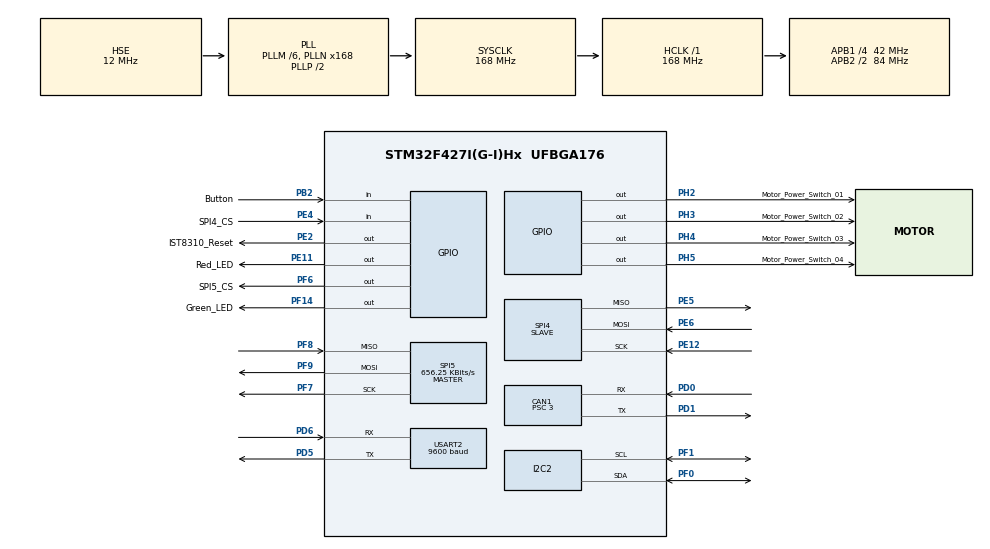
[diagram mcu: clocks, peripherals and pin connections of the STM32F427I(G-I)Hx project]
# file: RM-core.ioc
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CAN1.ABOM=ENABLE
CAN1.BS1=CAN_BS1_9TQ
CAN1.BS2=CAN_BS2_4TQ
CAN1.CalculateTimeQuantum=71.42857142857143
CAN1.Prescaler=3
FREERTOS.Tasks01=defaultTask,24,3000,StartDefaultTask,Default,NULL,Dynamic,NULL,NULL;myTask02,24,1024,StartTask02,Default,NULL,Static,myTask02Buffer,myTask02ControlBlock
FREERTOS.configTOTAL_HEAP_SIZE=15360
Mcu.Family=STM32F4
Mcu.Name=STM32F427I(G-I)Hx
Mcu.Package=UFBGA176
NVIC.CAN1_RX0_IRQn=true\:5\:0\:false\:false\:true\:true\:true\:true
NVIC.CAN1_TX_IRQn=true\:5\:0\:false\:false\:true\:true\:true\:true
NVIC.PriorityGroup=NVIC_PRIORITYGROUP_4
NVIC.TIM8_BRK_TIM12_IRQn=true\:0\:0\:false\:false\:true\:false\:false\:true
NVIC.TimeBase=TIM8_BRK_TIM12_IRQn
NVIC.TimeBaseIP=TIM12
NVIC.USART2_IRQn=true\:5\:0\:false\:false\:true\:true\:true\:true
PB2/BOOT1.GPIO_Label=Button
PB2/BOOT1.Signal=GPIO_Input
PD0.Mode=Master
PD0.Signal=CAN1_RX
PD1.Mode=Master
PD1.Signal=CAN1_TX
PD5.Mode=Asynchronous
PD5.Signal=USART2_TX
PD6.Mode=Asynchronous
PD6.Signal=USART2_RX
PE11.GPIO_Label=Red_LED
PE11.Signal=GPIO_Output
PE12.Mode=Full_Duplex_Slave
PE12.Signal=SPI4_SCK
PE2.GPIO_Label=IST8310_Reset
PE2.GPIO_Speed=GPIO_SPEED_FREQ_LOW
PE2.PinState=GPIO_PIN_SET
PE2.Signal=GPIO_Output
PE4.GPIO_Label=SPI4_CS
PE4.Signal=GPIO_Input
PE5.Mode=Full_Duplex_Slave
PE5.Signal=SPI4_MISO
PE6.Mode=Full_Duplex_Slave
PE6.Signal=SPI4_MOSI
PF0.Mode=I2C
PF0.Signal=I2C2_SDA
PF1.Mode=I2C
PF1.Signal=I2C2_SCL
PF14.GPIO_Label=Green_LED
PF14.Signal=GPIO_Output
PF6.GPIO_Label=SPI5_CS
PF6.GPIO_Speed=GPIO_SPEED_FREQ_VERY_HIGH
PF6.PinState=GPIO_PIN_SET
PF6.Signal=GPIO_Output
PF7.Mode=Full_Duplex_Master
PF7.Signal=SPI5_SCK
PF8.Mode=Full_Duplex_Master
PF8.Signal=SPI5_MISO
PF9.Mode=Full_Duplex_Master
PF9.Signal=SPI5_MOSI
PH0/OSC_IN.Mode=HSE-External-Oscillator
PH0/OSC_IN.Signal=RCC_OSC_IN
PH1/OSC_OUT.Mode=HSE-External-Oscillator
PH1/OSC_OUT.Signal=RCC_OSC_OUT
PH2.GPIO_Label=Motor_Power_Switch_01
PH2.Signal=GPIO_Output
PH3.GPIO_Label=Motor_Power_Switch_02
PH3.Signal=GPIO_Output
PH4.GPIO_Label=Motor_Power_Switch_03
PH4.Signal=GPIO_Output
PH5.GPIO_Label=Motor_Power_Switch_04
PH5.Signal=GPIO_Output
ProjectManager.HeapSize=0x200
ProjectManager.StackSize=0x400
ProjectManager.TargetToolchain=Makefile
RCC.48MHZClocksFreq_Value=84000000
RCC.AHBFreq_Value=168000000
RCC.APB1CLKDivider=RCC_HCLK_DIV4
RCC.APB1Freq_Value=42000000
RCC.APB1TimFreq_Value=84000000
RCC.APB2CLKDivider=RCC_HCLK_DIV2
RCC.APB2Freq_Value=84000000
RCC.APB2TimFreq_Value=168000000
RCC.CortexFreq_Value=168000000
RCC.HCLKFreq_Value=168000000
RCC.HSE_VALUE=12000000
RCC.HSI_VALUE=16000000
RCC.LSE_VALUE=32768
RCC.PLLM=6
RCC.PLLN=168
RCC.PLLSourceVirtual=RCC_PLLSOURCE_HSE
RCC.SYSCLKFreq_VALUE=168000000
RCC.SYSCLKSource=RCC_SYSCLKSOURCE_PLLCLK
RCC.VCOOutputFreq_Value=336000000
SPI4.CLKPhase=SPI_PHASE_1EDGE
SPI4.CRCCalculation=SPI_CRCCALCULATION_DISABLE
SPI4.Direction=SPI_DIRECTION_2LINES
SPI4.Mode=SPI_MODE_SLAVE
SPI4.TIMode=SPI_TIMODE_DISABLE
SPI4.VirtualType=VM_SLAVE
SPI5.BaudRatePrescaler=SPI_BAUDRATEPRESCALER_128
SPI5.CalculateBaudRate=656.25 KBits/s
SPI5.Direction=SPI_DIRECTION_2LINES
SPI5.Mode=SPI_MODE_MASTER
SPI5.VirtualType=VM_MASTER
USART2.BaudRate=9600
USART2.VirtualMode=VM_ASYNC
VP_FREERTOS_VS_CMSIS_V2.Mode=CMSIS_V2
VP_SYS_VS_tim12.Mode=TIM12
board=custom

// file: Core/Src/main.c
/* USER CODE BEGIN Header */
/**
  ******************************************************************************
  * @file           : main.c
  * @brief          : Main program body
  ******************************************************************************
  * @attention
  *
  * <h2><center>&copy; Copyright (c) 2020 STMicroelectronics.
  * All rights reserved.</center></h2>
  *
  * This software component is licensed by ST under Ultimate Liberty license
  * SLA0044, the "License"; You may not use this file except in compliance with
  * the License. You may obtain a copy of the License at:
  *                             www.st.com/SLA0044
  *
  ******************************************************************************
  */
/* USER CODE END Header */

#include "main.h"
#include "cmsis_os.h"

CAN_HandleTypeDef hcan1;

I2C_HandleTypeDef hi2c2;

SPI_HandleTypeDef hspi4;
SPI_HandleTypeDef hspi5;

UART_HandleTypeDef huart2;

typedef StaticTask_t osStaticThreadDef_t;
osThreadId_t defaultTaskHandle;
osThreadId_t myTask02Handle;
uint32_t myTask02Buffer[ 1024 ];
osStaticThreadDef_t myTask02ControlBlock;

void SystemClock_Config(void);
static void MX_GPIO_Init(void);
static void MX_USART2_UART_Init(void);
static void MX_CAN1_Init(void);
static void MX_SPI4_Init(void);
static void MX_SPI5_Init(void);
static void MX_I2C2_Init(void);
void StartDefaultTask(void *argument);
void StartTask02(void *argument);

int main(void)
{

  /* MCU Configuration--------------------------------------------------------*/

  /* Reset of all peripherals, Initializes the Flash interface and the Systick. */
  HAL_Init();

  /* Configure the system clock */
  SystemClock_Config();

  /* Initialize all configured peripherals */
  MX_GPIO_Init();
  MX_USART2_UART_Init();
  MX_CAN1_Init();
  MX_SPI4_Init();
  MX_SPI5_Init();
  MX_I2C2_Init();

  osKernelInitialize();

  /* Create the thread(s) */
  /* definition and creation of defaultTask */
  const osThreadAttr_t defaultTask_attributes = {
    .name = "defaultTask",
    .priority = (osPriority_t) osPriorityNormal,
    .stack_size = 3000
  };
  defaultTaskHandle = osThreadNew(StartDefaultTask, NULL, &defaultTask_attributes);

  /* definition and creation of myTask02 */
  const osThreadAttr_t myTask02_attributes = {
    .name = "myTask02",
    .stack_mem = &myTask02Buffer[0],
    .stack_size = sizeof(myTask02Buffer),
    .cb_mem = &myTask02ControlBlock,
    .cb_size = sizeof(myTask02ControlBlock),
    .priority = (osPriority_t) osPriorityNormal,
  };
  myTask02Handle = osThreadNew(StartTask02, NULL, &myTask02_attributes);

  /* Start scheduler */
  osKernelStart();

  /* We should never get here as control is now taken by the scheduler */

  /* Infinite loop */
  while (1)
  {

  }
}

void SystemClock_Config(void)
{
  RCC_OscInitTypeDef RCC_OscInitStruct = {0};
  RCC_ClkInitTypeDef RCC_ClkInitStruct = {0};

  /** Configure the main internal regulator output voltage
  */
  __HAL_RCC_PWR_CLK_ENABLE();
  __HAL_PWR_VOLTAGESCALING_CONFIG(PWR_REGULATOR_VOLTAGE_SCALE1);
  /** Initializes the CPU, AHB and APB busses clocks
  */
  RCC_OscInitStruct.OscillatorType = RCC_OSCILLATORTYPE_HSE;
  RCC_OscInitStruct.HSEState = RCC_HSE_ON;
  RCC_OscInitStruct.PLL.PLLState = RCC_PLL_ON;
  RCC_OscInitStruct.PLL.PLLSource = RCC_PLLSOURCE_HSE;
  RCC_OscInitStruct.PLL.PLLM = 6;
  RCC_OscInitStruct.PLL.PLLN = 168;
  RCC_OscInitStruct.PLL.PLLP = RCC_PLLP_DIV2;
  RCC_OscInitStruct.PLL.PLLQ = 4;
  if (HAL_RCC_OscConfig(&RCC_OscInitStruct) != HAL_OK)
  {
    Error_Handler();
  }
  /** Initializes the CPU, AHB and APB busses clocks
  */
  RCC_ClkInitStruct.ClockType = RCC_CLOCKTYPE_HCLK|RCC_CLOCKTYPE_SYSCLK
                              |RCC_CLOCKTYPE_PCLK1|RCC_CLOCKTYPE_PCLK2;
  RCC_ClkInitStruct.SYSCLKSource = RCC_SYSCLKSOURCE_PLLCLK;
  RCC_ClkInitStruct.AHBCLKDivider = RCC_SYSCLK_DIV1;
  RCC_ClkInitStruct.APB1CLKDivider = RCC_HCLK_DIV4;
  RCC_ClkInitStruct.APB2CLKDivider = RCC_HCLK_DIV2;

  if (HAL_RCC_ClockConfig(&RCC_ClkInitStruct, FLASH_LATENCY_5) != HAL_OK)
  {
    Error_Handler();
  }
}

static void MX_CAN1_Init(void)
{

  hcan1.Instance = CAN1;
  hcan1.Init.Prescaler = 3;
  hcan1.Init.Mode = CAN_MODE_NORMAL;
  hcan1.Init.SyncJumpWidth = CAN_SJW_1TQ;
  hcan1.Init.TimeSeg1 = CAN_BS1_9TQ;
  hcan1.Init.TimeSeg2 = CAN_BS2_4TQ;
  hcan1.Init.TimeTriggeredMode = DISABLE;
  hcan1.Init.AutoBusOff = ENABLE;
  hcan1.Init.AutoWakeUp = DISABLE;
  hcan1.Init.AutoRetransmission = DISABLE;
  hcan1.Init.ReceiveFifoLocked = DISABLE;
  hcan1.Init.TransmitFifoPriority = DISABLE;
  if (HAL_CAN_Init(&hcan1) != HAL_OK)
  {
    Error_Handler();
  }

}

static void MX_I2C2_Init(void)
{

  hi2c2.Instance = I2C2;
  hi2c2.Init.ClockSpeed = 100000;
  hi2c2.Init.DutyCycle = I2C_DUTYCYCLE_2;
  hi2c2.Init.OwnAddress1 = 0;
  hi2c2.Init.AddressingMode = I2C_ADDRESSINGMODE_7BIT;
  hi2c2.Init.DualAddressMode = I2C_DUALADDRESS_DISABLE;
  hi2c2.Init.OwnAddress2 = 0;
  hi2c2.Init.GeneralCallMode = I2C_GENERALCALL_DISABLE;
  hi2c2.Init.NoStretchMode = I2C_NOSTRETCH_DISABLE;
  if (HAL_I2C_Init(&hi2c2) != HAL_OK)
  {
    Error_Handler();
  }
  /** Configure Analogue filter
  */
  if (HAL_I2CEx_ConfigAnalogFilter(&hi2c2, I2C_ANALOGFILTER_ENABLE) != HAL_OK)
  {
    Error_Handler();
  }
  /** Configure Digital filter
  */
  if (HAL_I2CEx_ConfigDigitalFilter(&hi2c2, 0) != HAL_OK)
  {
    Error_Handler();
  }

}

static void MX_SPI4_Init(void)
{

  /* SPI4 parameter configuration*/
  hspi4.Instance = SPI4;
  hspi4.Init.Mode = SPI_MODE_SLAVE;
  hspi4.Init.Direction = SPI_DIRECTION_2LINES;
  hspi4.Init.DataSize = SPI_DATASIZE_8BIT;
  hspi4.Init.CLKPolarity = SPI_POLARITY_LOW;
  hspi4.Init.CLKPhase = SPI_PHASE_1EDGE;
  hspi4.Init.NSS = SPI_NSS_SOFT;
  hspi4.Init.FirstBit = SPI_FIRSTBIT_MSB;
  hspi4.Init.TIMode = SPI_TIMODE_DISABLE;
  hspi4.Init.CRCCalculation = SPI_CRCCALCULATION_DISABLE;
  hspi4.Init.CRCPolynomial = 10;
  if (HAL_SPI_Init(&hspi4) != HAL_OK)
  {
    Error_Handler();
  }

}

static void MX_SPI5_Init(void)
{

  /* SPI5 parameter configuration*/
  hspi5.Instance = SPI5;
  hspi5.Init.Mode = SPI_MODE_MASTER;
  hspi5.Init.Direction = SPI_DIRECTION_2LINES;
  hspi5.Init.DataSize = SPI_DATASIZE_8BIT;
  hspi5.Init.CLKPolarity = SPI_POLARITY_LOW;
  hspi5.Init.CLKPhase = SPI_PHASE_1EDGE;
  hspi5.Init.NSS = SPI_NSS_SOFT;
  hspi5.Init.BaudRatePrescaler = SPI_BAUDRATEPRESCALER_128;
  hspi5.Init.FirstBit = SPI_FIRSTBIT_MSB;
  hspi5.Init.TIMode = SPI_TIMODE_DISABLE;
  hspi5.Init.CRCCalculation = SPI_CRCCALCULATION_DISABLE;
  hspi5.Init.CRCPolynomial = 10;
  if (HAL_SPI_Init(&hspi5) != HAL_OK)
  {
    Error_Handler();
  }

}

static void MX_USART2_UART_Init(void)
{

  huart2.Instance = USART2;
  huart2.Init.BaudRate = 9600;
  huart2.Init.WordLength = UART_WORDLENGTH_8B;
  huart2.Init.StopBits = UART_STOPBITS_1;
  huart2.Init.Parity = UART_PARITY_NONE;
  huart2.Init.Mode = UART_MODE_TX_RX;
  huart2.Init.HwFlowCtl = UART_HWCONTROL_NONE;
  huart2.Init.OverSampling = UART_OVERSAMPLING_16;
  if (HAL_UART_Init(&huart2) != HAL_OK)
  {
    Error_Handler();
  }

}

static void MX_GPIO_Init(void)
{
  GPIO_InitTypeDef GPIO_InitStruct = {0};

  /* GPIO Ports Clock Enable */
  __HAL_RCC_GPIOE_CLK_ENABLE();
  __HAL_RCC_GPIOD_CLK_ENABLE();
  __HAL_RCC_GPIOF_CLK_ENABLE();
  __HAL_RCC_GPIOH_CLK_ENABLE();
  __HAL_RCC_GPIOB_CLK_ENABLE();

  /*Configure GPIO pin Output Level */
  HAL_GPIO_WritePin(IST8310_Reset_GPIO_Port, IST8310_Reset_Pin, GPIO_PIN_SET);

  /*Configure GPIO pin Output Level */
  HAL_GPIO_WritePin(GPIOH, Motor_Power_Switch_01_Pin|Motor_Power_Switch_02_Pin|Motor_Power_Switch_03_Pin|Motor_Power_Switch_04_Pin, GPIO_PIN_RESET);

  /*Configure GPIO pin Output Level */
  HAL_GPIO_WritePin(SPI5_CS_GPIO_Port, SPI5_CS_Pin, GPIO_PIN_SET);

  /*Configure GPIO pin Output Level */
  HAL_GPIO_WritePin(Red_LED_GPIO_Port, Red_LED_Pin, GPIO_PIN_RESET);

  /*Configure GPIO pin Output Level */
  HAL_GPIO_WritePin(Green_LED_GPIO_Port, Green_LED_Pin, GPIO_PIN_RESET);

  /*Configure GPIO pins : IST8310_Reset_Pin Red_LED_Pin */
  GPIO_InitStruct.Pin = IST8310_Reset_Pin|Red_LED_Pin;
  GPIO_InitStruct.Mode = GPIO_MODE_OUTPUT_PP;
  GPIO_InitStruct.Pull = GPIO_NOPULL;
  GPIO_InitStruct.Speed = GPIO_SPEED_FREQ_LOW;
  HAL_GPIO_Init(GPIOE, &GPIO_InitStruct);

  /*Configure GPIO pin : SPI4_CS_Pin */
  GPIO_InitStruct.Pin = SPI4_CS_Pin;
  GPIO_InitStruct.Mode = GPIO_MODE_INPUT;
  GPIO_InitStruct.Pull = GPIO_NOPULL;
  HAL_GPIO_Init(SPI4_CS_GPIO_Port, &GPIO_InitStruct);

  /*Configure GPIO pins : Motor_Power_Switch_01_Pin Motor_Power_Switch_02_Pin Motor_Power_Switch_03_Pin Motor_Power_Switch_04_Pin */
  GPIO_InitStruct.Pin = Motor_Power_Switch_01_Pin|Motor_Power_Switch_02_Pin|Motor_Power_Switch_03_Pin|Motor_Power_Switch_04_Pin;
  GPIO_InitStruct.Mode = GPIO_MODE_OUTPUT_PP;
  GPIO_InitStruct.Pull = GPIO_NOPULL;
  GPIO_InitStruct.Speed = GPIO_SPEED_FREQ_LOW;
  HAL_GPIO_Init(GPIOH, &GPIO_InitStruct);

  /*Configure GPIO pin : SPI5_CS_Pin */
  GPIO_InitStruct.Pin = SPI5_CS_Pin;
  GPIO_InitStruct.Mode = GPIO_MODE_OUTPUT_PP;
  GPIO_InitStruct.Pull = GPIO_NOPULL;
  GPIO_InitStruct.Speed = GPIO_SPEED_FREQ_VERY_HIGH;
  HAL_GPIO_Init(SPI5_CS_GPIO_Port, &GPIO_InitStruct);

  /*Configure GPIO pin : Button_Pin */
  GPIO_InitStruct.Pin = Button_Pin;
  GPIO_InitStruct.Mode = GPIO_MODE_INPUT;
  GPIO_InitStruct.Pull = GPIO_NOPULL;
  HAL_GPIO_Init(Button_GPIO_Port, &GPIO_InitStruct);

  /*Configure GPIO pin : Green_LED_Pin */
  GPIO_InitStruct.Pin = Green_LED_Pin;
  GPIO_InitStruct.Mode = GPIO_MODE_OUTPUT_PP;
  GPIO_InitStruct.Pull = GPIO_NOPULL;
  GPIO_InitStruct.Speed = GPIO_SPEED_FREQ_LOW;
  HAL_GPIO_Init(Green_LED_GPIO_Port, &GPIO_InitStruct);

}

void StartDefaultTask(void *argument)
{
  /* USER CODE BEGIN 5 */
  /* Infinite loop */
  setup();
  for(;;)
  {
    loop0();
    //osDelay(1);
  }
  /* USER CODE END 5 */
}

void StartTask02(void *argument)
{
  /* USER CODE BEGIN StartTask02 */
  /* Infinite loop */
  for(;;)
  {
    loop1();
    //osDelay(1);
  }
  /* USER CODE END StartTask02 */
}

void HAL_TIM_PeriodElapsedCallback(TIM_HandleTypeDef *htim)
{
  /* USER CODE BEGIN Callback 0 */
  call_this_inside_HAL_TIM_PeriodElaspedCallback(htim);
  /* USER CODE END Callback 0 */
  if (htim->Instance == TIM12) {
    HAL_IncTick();
  }
}

void Error_Handler(void)
{
}

/************************ (C) COPYRIGHT STMicroelectronics *****END OF FILE****/
